# M2003 register map
File version: 1.0
Registers are 32-bit, read-write, reset 0x0 unless marked. A register's access mark holds for its fields unless they carry their own. Offsets are from the block's base; [hi:lo] are bit positions; {n}, {i} and the like mark numbered series; 'fields as' and 'values as' point back to an identical list.

## GPIO — GPIO Register Map
Base 0x40004000
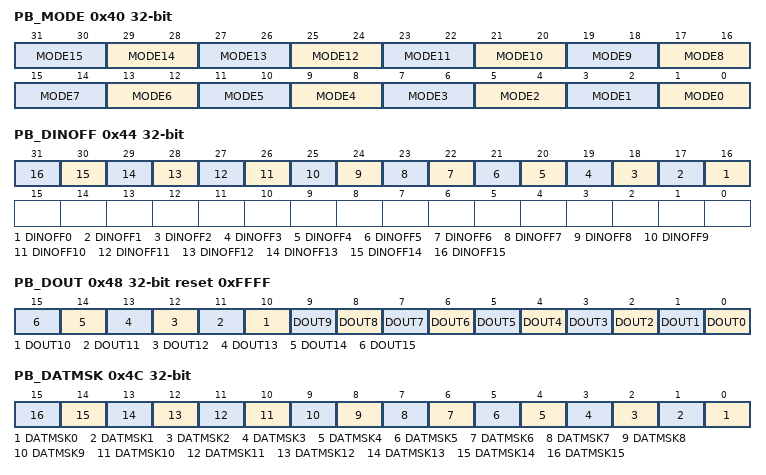
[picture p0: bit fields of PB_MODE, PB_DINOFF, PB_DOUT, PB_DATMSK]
0x40 PB_MODE reset not defined — PB I/O Mode Control
  [all] fields
    0=Px.n is in Input mode (tri-state); 1=Px.n is in Push-pull Output mode; 2=Px.n is in Open-drain Output mode; 3=Px.n is in Quasi-bidirectional mode
  [2n+1:2n] MODE{n} (n=0..15) — Port B-F I/O Pin[n] Mode Control. Determine each I/O mode of Px.n pins. Note 1: The initial value of this field is defined by CIOINI (CONFIG0 [10]).If CIOINI is set to 0, the default value is 0xFFFF_FFFF and all pins will be quasi-bidirectional mode after chip powered on.If CIOINI is set to 1, the default value is 0x0000_0000 and all pins will be input mode after chip powered on. Note 2: The PB.6/PB.10/PC.0~13/PC.15/PE.0~15/ PF.3~15 pins are ignored. Note 3: If MFOS is enabled then GPIO mode setting is ignored.
0x44 PB_DINOFF — PB Digital Input Path Disable Control
  [all] fields
    0=Px.n digital input path Enabled; 1=Px.n digital input path Disabled (digital input tied to low)
  [n+16] DINOFF{n} (n=0..15) — Port B-F Pin[n] Digital Input Path Disable Bit. Each of these bits is used to control if the digital input path of corresponding Px.n pin is disabled. If input is analog signal, users can disable Px.n digital input path to avoid input current leakage. Note: The PB.6/PB.10/PC.0~13/PC.15/PE.0~15/ PF.3~15 pins are ignored.
0x48 PB_DOUT reset 0xFFFF — PB Data Output Value
  [all] fields
    0=Px.n will drive Low if the Px.n pin is configured as Push-pull output, Open-drain output or Quasi-bidirectional mode; 1=Px.n will drive High if the Px.n pin is configured as Push-pull output or Quasi-bidirectional mode
  [n] DOUT{n} (n=0..15) — Port B-F Pin[n] Output Value. Each of these bits controls the status of a Px.n pin when the Px.n is configured as Push-pull output, Open-drain output or Quasi-bidirectional mode. Note: The PB.6/PB.10/PC.0~13/PC.15/PE.0~15/ PF.3~15 pins are ignored.
0x4C PB_DATMSK — PB Data Output Write Mask
  [all] fields
    0=Corresponding DOUT (Px_DOUT[n]) bit can be updated; 1=Corresponding DOUT (Px_DOUT[n]) bit protected
  [n] DATMSK{n} (n=0..15) — Port B-F Pin[n] Data Output Write Mask. These bits are used to protect the corresponding DOUT (Px_DOUT[n]) bit. When the DATMSK (Px_DATMSK[n]) bit is set to 1, the corresponding DOUT (Px_DOUT[n]) bit is protected. If the write signal is masked, writing data to the protect bit is ineffective. Note 1: This function only protects the corresponding DOUT (Px_DOUT[n]) bit, and will not protect the corresponding PDIO (Pxn_PDIO[0]) bit. Note 2: The PB.6/PB.10/PC.0~13/PC.15/PE.0~15/ PF.3~15 pins are ignored.
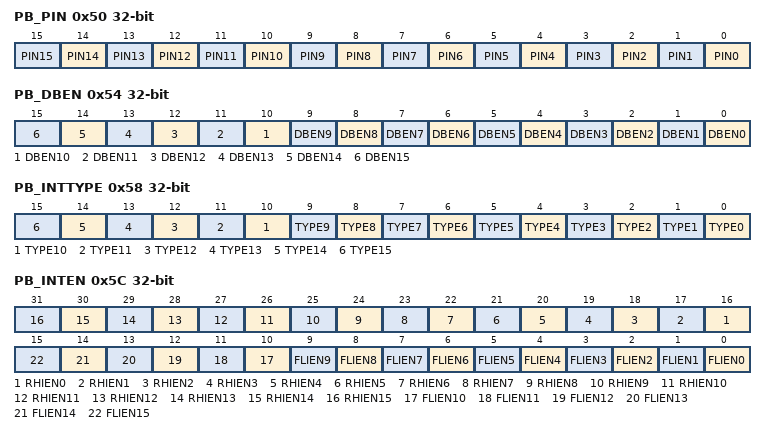
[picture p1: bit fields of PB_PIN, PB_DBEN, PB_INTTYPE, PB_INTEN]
0x50 PB_PIN ro (reset mask 0xFFFF0000) — PB Pin Value
  [all] fields
    0=The corresponding pin status is low; 1=The corresponding pin status is high
  [n] PIN{n} (n=0..15) — Port B-F Pin[n] Pin Value. Each bit of the register reflects the actual status of the respective Px.n pin. Note: The PB.6/PB.10/PC.0~13/PC.15/PE.0~14/ PF.3~15 pins are ignored.
0x54 PB_DBEN — PB De-bounce Enable Control Register
  [all] fields
    0=Px.n de-bounce function Disabled; 1=Px.n de-bounce function Enabled
  [n] DBEN{n} (n=0..15) — Port B-F Pin[n] Input Signal De-bounce Enable Bit. The DBEN[n] bit is used to enable the de-bounce function for each corresponding bit. If the input signal pulse width cannot be sampled by continuous two de-bounce sample cycle, the input signal transition is seen as the signal bounce and will not trigger the interrupt. The de-bounce clock source is controlled by DBCLKSRC (Px_DBCTL [4]), one de-bounce sample cycle period is controlled by DBCLKSEL (Px_DBCTL [3:0]). The de-bounce function is valid only for edge triggered interrupt. If the interrupt mode is level triggered, the de-bounce enable bit is ineffective. Note: The PB.6/PB.10/PC.0~13/PC.15/PE.0~14/ PF.3~15 pins are ignored.
0x58 PB_INTTYPE — PB Interrupt Trigger Type Control
  [all] fields
    0=Edge trigger interrupt; 1=Level trigger interrupt
  [n] TYPE{n} (n=0..15) — Port B-F Pin[n] Edge or Level Detection Interrupt Trigger Type Control. TYPE (Px_INTTYPE[n]) bit is used to control the triggered interrupt is by level trigger or by edge trigger. If the interrupt is by edge trigger, the trigger source can be controlled by de-bounce. If the interrupt is by level trigger, the input source is sampled by one HCLK clock and generates the interrupt. If the pin is set as the level trigger interrupt, only one level can be set on the registers RHIEN (Px_INTEN[n+16])/FLIEN (Px_INTEN[n]). If both levels to trigger interrupt are set, the setting has no effect and no interrupt will occur. The de-bounce function is valid only for edge triggered interrupt. If the interrupt mode is level triggered, the de-bounce enable bit is ineffective. Note: The PB.6/PB.10/PC.0~13/PC.15/PE.0~14/ PF.3~15 pins are ignored.
0x5C PB_INTEN — PB Interrupt Enable Control Register
  [n+16] RHIEN{n} (n=0..15) — Port B-F Pin[n] Rising Edge or High Level Interrupt Trigger Type Enable Bit. The RHIEN (Px_INTEN[n+16]) bit is used to enable the interrupt for each of the corresponding input Px.n pin. Set bit to 1 also enable the pin wake-up function. When setting the RHIEN (Px_INTEN[n+16]) bit to 1 : If the interrupt is level trigger (TYPE (Px_INTTYPE[n]) bit is set to 1), the input Px.n pin will generate the interrupt while this pin state is at high level. If the interrupt is edge trigger (TYPE (Px_INTTYPE[n]) bit is set to 0), the input Px.n pin will generate the interrupt while this pin state changed from low to high. Note: The P PB.6/PB.10/PC.0~13/PC.15/PE.0~14/ PF.3~15 pins are ignored.
    0=Px.n level high or low to high interrupt Disabled; 1=Px.n level high or low to high interrupt Enabled
  [n] FLIEN{n} (n=0..15) — Port B-F Pin[n] Falling Edge or Low Level Interrupt Trigger Type Enable Bit. The FLIEN (Px_INTEN[n]) bit is used to enable the interrupt for each of the corresponding input Px.n pin. Set bit to 1 also enable the pin wake-up function. When setting the FLIEN (Px_INTEN[n]) bit to 1 : If the interrupt is level trigger (TYPE (Px_INTTYPE[n]) bit is set to 1), the input Px.n pin will generate the interrupt while this pin state is at low level. If the interrupt is edge trigger(TYPE (Px_INTTYPE[n]) bit is set to 0), the input Px.n pin will generate the interrupt while this pin state changed from high to low. Note: The PB.6/PB.10/PC.0~13/PC.15/PE.0~14/ PF.3~15 pins are ignored.
    0=Px.n level low or high to low interrupt Disabled; 1=Px.n level low or high to low interrupt Enabled
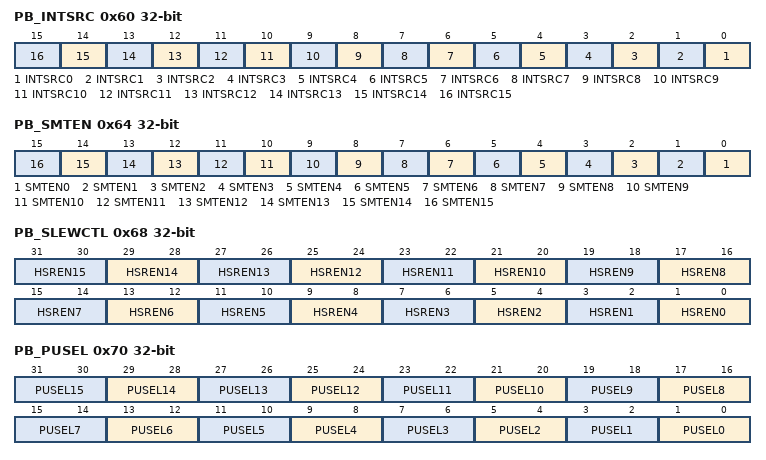
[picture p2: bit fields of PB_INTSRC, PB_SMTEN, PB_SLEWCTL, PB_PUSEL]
0x60 PB_INTSRC (reset mask 0xFFFF0000) — PB Interrupt Source Flag
  [all] fields
    0=No action. No interrupt at Px.n; 1=Clear the corresponding pending interrupt. Px.n generates an interrupt
  [n] INTSRC{n} (n=0..15) — Port B-F Pin[n] Interrupt Source Flag. Write Operation: Note: The PB.6/PB.10/PC.0~13/PC.15/PE.0~14/ PF.3~15 pins are ignored.
0x64 PB_SMTEN — PB Input Schmitt Trigger Enable Register
  [all] fields
    0=Px.n input schmitt trigger function Disabled; 1=Px.n input schmitt trigger function Enabled
  [n] SMTEN{n} (n=0..15) — Port B-F Pin[n] Input Schmitt Trigger Enable Bit. Note: The PB.6/PB.10/PC.0~13/PC.15/PE.0~15/ PF.3~15 pins are ignored.
0x68 PB_SLEWCTL — PB High Slew Rate Control Register
  [all] fields
    0=Px.n output with normal slew rate mode; 1=Px.n output with high slew rate mode; 2=Px.n output with high slew rate mode
  [2n+1:2n] HSREN{n} (n=0..15) — Port B-F Pin[n] High Slew Rate Control. Note 1: The PB.6/PB.10/PC.0~13/PC.15/PE.0~15/ PF.3~15 pins are ignored. Note 2: Please refer to the Datasheet for detailed pin operation voltage information about VDD, VDDIO and VBAT electrical characteristics.
0x70 PB_PUSEL — PB Pull-up and Pull-down Selection Register
  [all] fields
    0=Px.n pull-up and pull-down disabled; 1=Px.n pull-up enabled; 2=Px.n pull-down enabled; 3=Px.n pull-up and pull- down disabled
  [2n+1:2n] PUSEL{n} (n=0..15) — Port B-F Pin[n] Pull-up and Pull-down Enable Register. Determine each I/O Pull-up/pull-down of Px.n pins. Note 1: Basically, the pull-up control and pull-down control has following behavior limitation. The independent pull-up control register only valid when MODEn set as input and open-drain mode even if I/O function is switched to multi-function pin. Ex: UARTx_RXD. The independent pull-down control register only valid when MODEn set as tri-state mode. When both pull-uppull-down is set as 1 at 'tri-state' mode, keep I/O in tri-state mode. Note 2: The PB.6/PB.10/PC.0~13/PC.15/PE.0~14/ PF.3~15 pins are ignored, PE.15 pin only support pull-up enabled or disalbed.
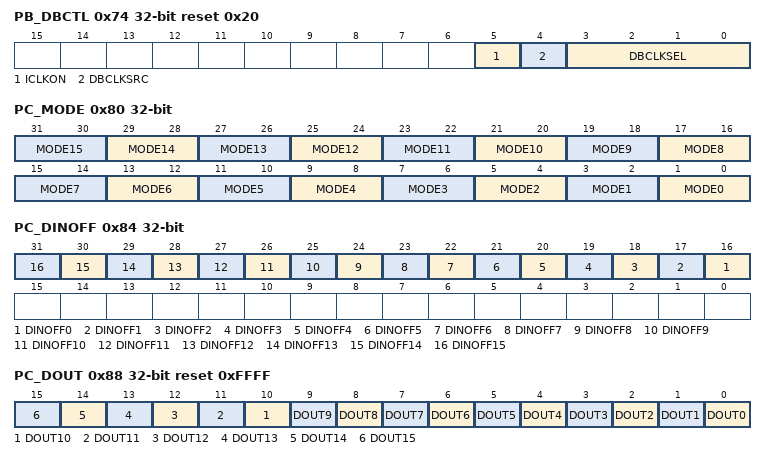
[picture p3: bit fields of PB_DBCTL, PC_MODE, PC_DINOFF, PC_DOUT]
0x74 PB_DBCTL reset 0x20 — PB Interrupt De-bounce Control Register
  [5] ICLKON — Interrupt Clock on Mode - Secure Only. Note 1: It is recommended to disable this bit to save system power if no special application concern. Note 2: This bit is only accessible from the Secure state.
    0=Edge detection circuit is active only if I/O pin corresponding RHIEN (Px_INTEN[n+16])/FLIEN (Px_INTEN[n]) bit is set to 1; 1=All I/O pins edge detection circuit is always active after reset
  [4] DBCLKSRC — De-bounce Counter Clock Source Selection - Secure only. Note: This bit is only accessible from the Secure state.
    0=De-bounce counter clock source is the HCLK; 1=De-bounce counter clock source is the 10 kHz internal low speed RC oscillator (LIRC)
  [3:0] DBCLKSEL — De-bounce Sampling Cycle Selection - Secure only. Note: These bits are only accessible from the Secure state.
    0=Sample interrupt input once per 1 clocks; 1=Sample interrupt input once per 2 clocks; 2=Sample interrupt input once per 4 clocks; 3=Sample interrupt input once per 8 clocks; 4=Sample interrupt input once per 16 clocks; 5=Sample interrupt input once per 32 clocks; 6=Sample interrupt input once per 64 clocks; 7=Sample interrupt input once per 128 clocks; 8=Sample interrupt input once per 256 clocks; 9=Sample interrupt input once per 2*256 clocks; 10=Sample interrupt input once per 4*256 clocks; 11=Sample interrupt input once per 8*256 clocks; 12=Sample interrupt input once per 16*256 clocks; 13=Sample interrupt input once per 32*256 clocks; 14=Sample interrupt input once per 64*256 clocks; 15=Sample interrupt input once per 128*256 clocks
0x80 PC_MODE reset not defined — PC I/O Mode Control
  fields as PB_MODE
0x84 PC_DINOFF — PC Digital Input Path Disable Control
  fields as PB_DINOFF
0x88 PC_DOUT reset 0xFFFF — PC Data Output Value
  fields as PB_DOUT
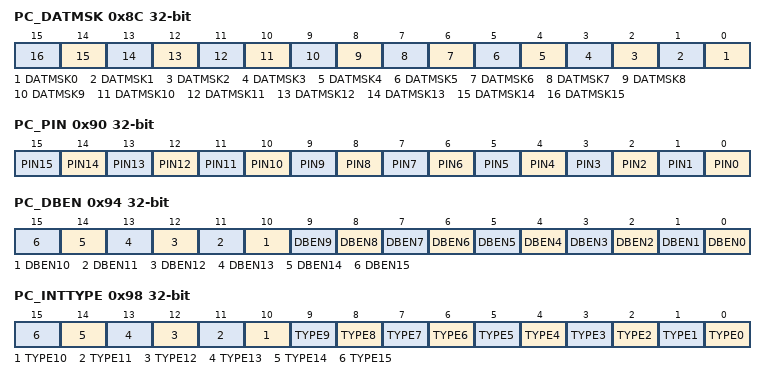
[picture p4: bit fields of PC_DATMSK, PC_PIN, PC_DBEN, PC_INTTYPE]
0x8C PC_DATMSK — PC Data Output Write Mask
  fields as PB_DATMSK
0x90 PC_PIN ro (reset mask 0xFFFF0000) — PC Pin Value
  fields as PB_PIN
0x94 PC_DBEN — PC De-bounce Enable Control Register
  fields as PB_DBEN
0x98 PC_INTTYPE — PC Interrupt Trigger Type Control
  fields as PB_INTTYPE
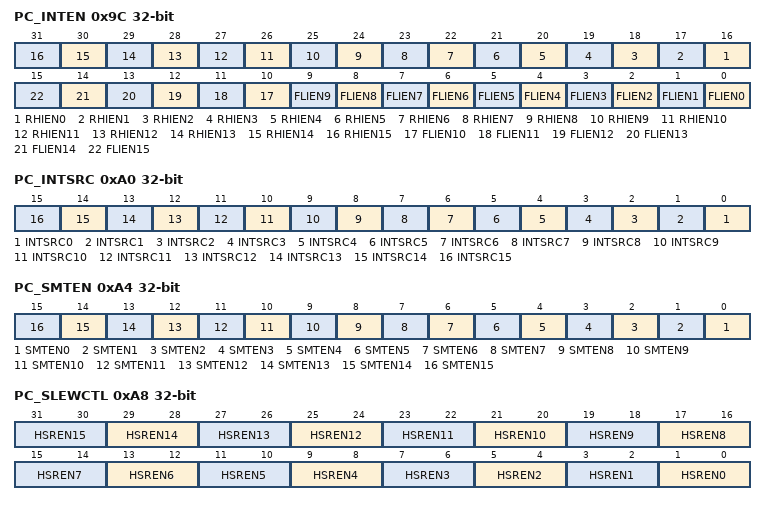
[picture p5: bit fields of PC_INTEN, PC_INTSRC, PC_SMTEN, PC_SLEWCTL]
0x9C PC_INTEN — PC Interrupt Enable Control Register
  fields as PB_INTEN
0xA0 PC_INTSRC (reset mask 0xFFFF0000) — PC Interrupt Source Flag
  fields as PB_INTSRC
0xA4 PC_SMTEN — PC Input Schmitt Trigger Enable Register
  fields as PB_SMTEN
0xA8 PC_SLEWCTL — PC High Slew Rate Control Register
  fields as PB_SLEWCTL
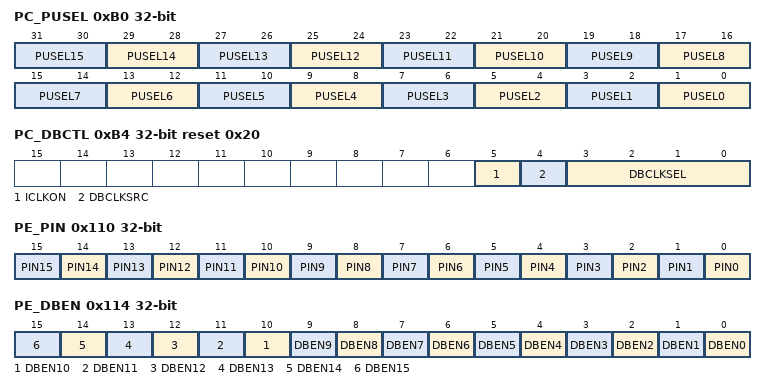
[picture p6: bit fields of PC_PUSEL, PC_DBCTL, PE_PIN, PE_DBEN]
0xB0 PC_PUSEL — PC Pull-up and Pull-down Selection Register
  fields as PB_PUSEL
0xB4 PC_DBCTL reset 0x20 — PC Interrupt De-bounce Control Register
  fields as PB_DBCTL
0x110 PE_PIN ro (reset mask 0xFFFF0000) — PE Pin Value
  fields as PB_PIN
0x114 PE_DBEN — PE De-bounce Enable Control Register
  fields as PB_DBEN
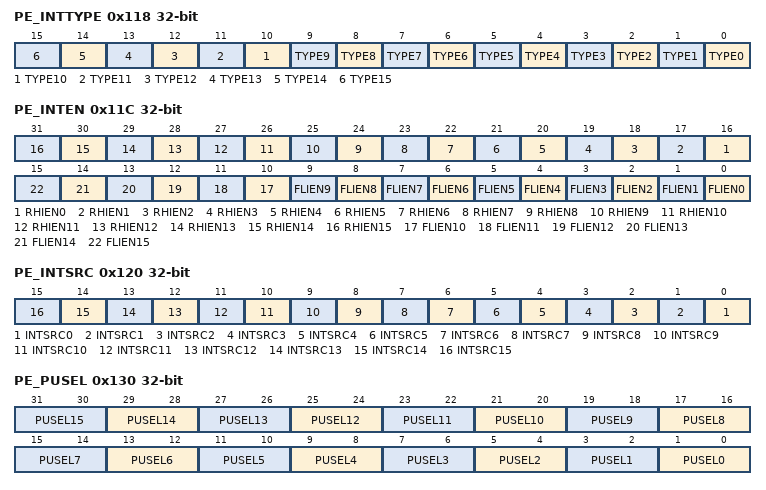
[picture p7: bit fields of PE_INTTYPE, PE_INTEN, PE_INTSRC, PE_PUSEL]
0x118 PE_INTTYPE — PE Interrupt Trigger Type Control
  fields as PB_INTTYPE
0x11C PE_INTEN — PE Interrupt Enable Control Register
  fields as PB_INTEN
0x120 PE_INTSRC (reset mask 0xFFFF0000) — PE Interrupt Source Flag
  fields as PB_INTSRC
0x130 PE_PUSEL — PE Pull-up Selection Register
  fields as PB_PUSEL
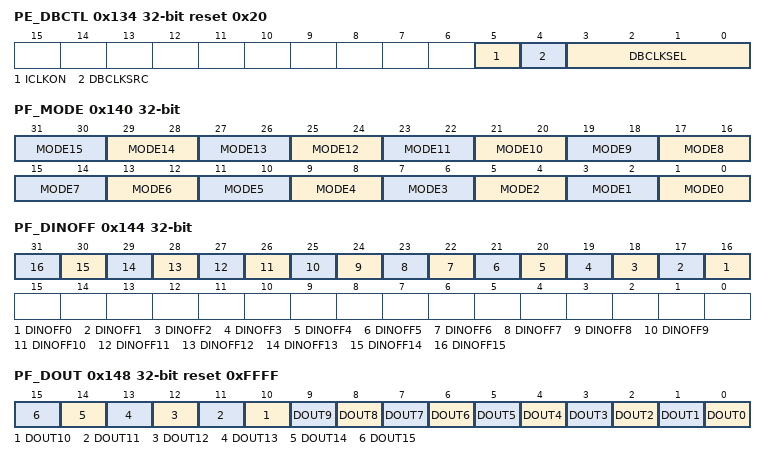
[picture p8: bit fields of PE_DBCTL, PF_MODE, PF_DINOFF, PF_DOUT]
0x134 PE_DBCTL reset 0x20 — PE Interrupt De-bounce Control Register
  fields as PB_DBCTL
0x140 PF_MODE reset not defined — PF I/O Mode Control
  fields as PB_MODE
0x144 PF_DINOFF — PF Digital Input Path Disable Control
  fields as PB_DINOFF
0x148 PF_DOUT reset 0xFFFF — PF Data Output Value
  fields as PB_DOUT
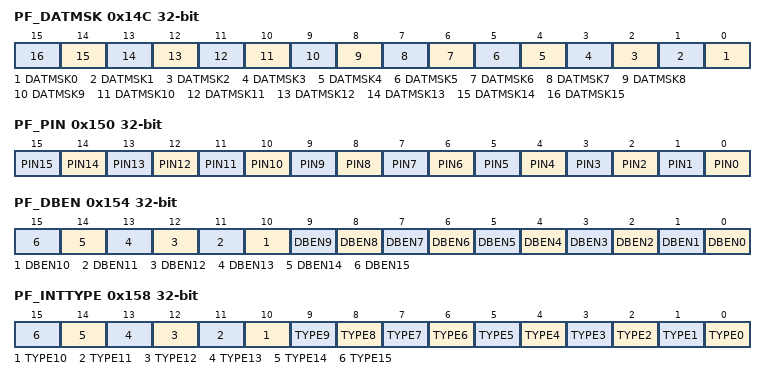
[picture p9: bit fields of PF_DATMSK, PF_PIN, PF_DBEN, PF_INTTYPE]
0x14C PF_DATMSK — PF Data Output Write Mask
  fields as PB_DATMSK
0x150 PF_PIN ro (reset mask 0xFFFF0000) — PF Pin Value
  fields as PB_PIN
0x154 PF_DBEN — PF De-bounce Enable Control Register
  fields as PB_DBEN
0x158 PF_INTTYPE — PF Interrupt Trigger Type Control
  fields as PB_INTTYPE
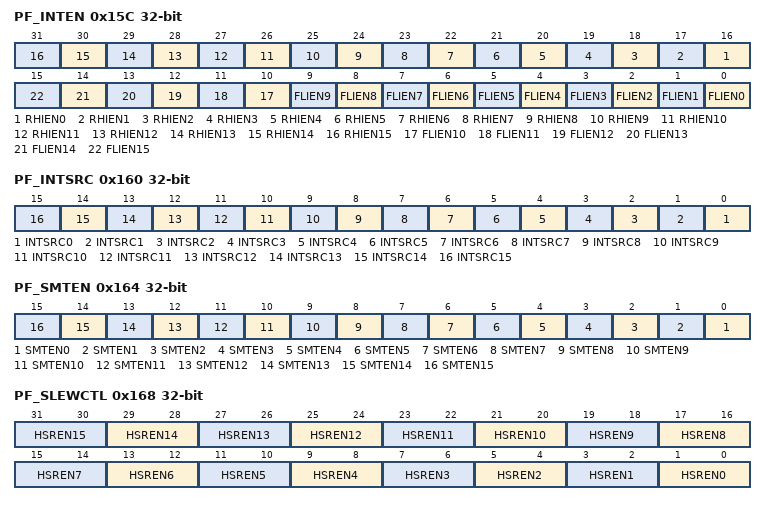
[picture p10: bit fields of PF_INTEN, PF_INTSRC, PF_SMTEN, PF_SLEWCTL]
0x15C PF_INTEN — PF Interrupt Enable Control Register
  fields as PB_INTEN
0x160 PF_INTSRC (reset mask 0xFFFF0000) — PF Interrupt Source Flag
  fields as PB_INTSRC
0x164 PF_SMTEN — PF Input Schmitt Trigger Enable Register
  fields as PB_SMTEN
0x168 PF_SLEWCTL — PF High Slew Rate Control Register
  fields as PB_SLEWCTL
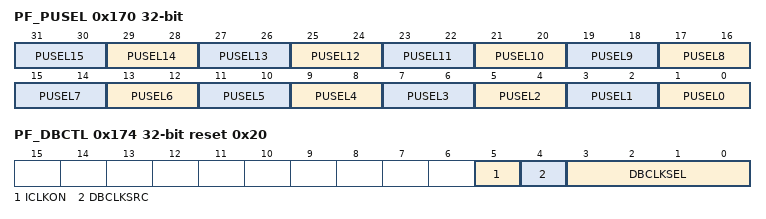
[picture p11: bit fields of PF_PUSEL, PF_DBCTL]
0x170 PF_PUSEL — PF Pull-up and Pull-down Selection Register
  fields as PB_PUSEL
0x174 PF_DBCTL reset 0x20 — PF Interrupt De-bounce Control Register
  fields as PB_DBCTL
{0x840+4i} PB{i}_PDIO (reset mask 0xFFFFFFF0) (i=0..15) — GPIO PB.n Pin Data Input/Output Register
  [0] PDIO — GPIO Px.n Pin Data Input/Output. Writing this bit can control one GPIO pin output value. Read this register to get GPIO pin status. For example, writing PB0_PDIO will reflect the written value to bit DOUT (PB_DOUT[0]), reading PB0_PDIO will return the value of PIN (PB_PIN[0]). Note 1: The writing operation will not be affected by register DATMSK (Px_DATMSK[n]). Note 2: The PB.6/PB.10/PC.0~13/PC.15/PE.0~14/ PF.3~15 pins are ignored. Note 3: The PE.15 pin is only input mode
    0=Corresponding GPIO pin set to low; 1=Corresponding GPIO pin set to high
{0x880+4i} PC{i}_PDIO (reset mask 0xFFFFFFF0) (i=0..15) — GPIO PC.n Pin Data Input/Output Register
  fields as PB0_PDIO
{0x900+4i} PE{i}_PDIO (reset mask 0xFFFFFFF0) (i=0..15) — GPIO PE.n Pin Data Input/Output Register
  fields as PB0_PDIO
{0x940+4i} PF{i}_PDIO (reset mask 0xFFFFFFF0) (i=0..15) — GPIO PF.n Pin Data Input/Output Register
  fields as PB0_PDIO
